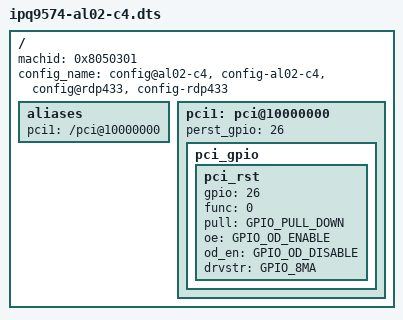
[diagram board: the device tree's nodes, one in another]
/*
 * Copyright (c) 2016-2021, The Linux Foundation. All rights reserved.
 *
 * Copyright (c) 2021-2023 Qualcomm Innovation Center, Inc. All rights reserved.
 *
 * This program is free software; you can redistribute it and/or modify
 * it under the terms of the GNU General Public License version 2 and
 * only version 2 as published by the Free Software Foundation.
 *
 * This program is distributed in the hope that it will be useful,
 * but WITHOUT ANY WARRANTY; without even the implied warranty of
 * MERCHANTABILITY or FITNESS FOR A PARTICULAR PURPOSE.  See the
 * GNU General Public License for more details.
 */

/dts-v1/;
#include "ipq9574-al02-c1.dts"
/ {
	machid = <0x8050301>;
	config_name = "config@al02-c4", "config-al02-c4", "config@rdp433", "config-rdp433";

	aliases {
		pci1 = "/pci@10000000";
	};

	pci1: pci@10000000 {
		status = "ok";
		perst_gpio = <26>;
		pci_gpio {
			pci_rst {
				gpio = <26>;
				func = <0>;
				pull = <GPIO_PULL_DOWN>;
				oe = <GPIO_OD_ENABLE>;
				od_en = <GPIO_OD_DISABLE>;
				drvstr = <GPIO_8MA>;
			};
		};
	};
};
